# SCR_TC3xx register map
Vendor: Infineon; File version: 1.0
Registers are 8-bit, read-write, reset 0x0 unless marked. A register's access mark holds for its fields unless they carry their own. Offsets are from the block's base; [hi:lo] are bit positions; {n}, {i} and the like mark numbered series; 'fields as' and 'values as' point back to an identical list.

## SCR_SCU — SCR System control unit: SFR paging, clocks, resets, power management, NMI, external interrupts, TriCore data exchange, input selection
Base 0x00040000
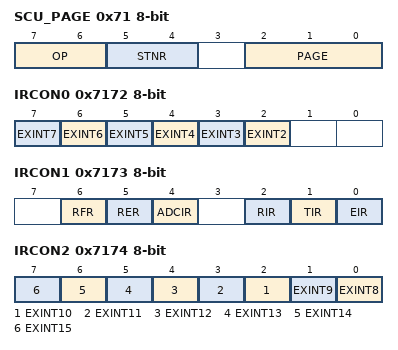
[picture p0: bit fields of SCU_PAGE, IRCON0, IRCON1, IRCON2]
0x71 SCU_PAGE — Page Register for SFRs (SFR 0xF1, RMAP 0)
  [7:6] OP — Operation. [w]
    0=PAGE_MANUAL0 (Manual page mode. The value of STNR is ignored and PAGE is directly written.); 1=PAGE_MANUAL1 (Manual page mode. The value of STNR is ignored and PAGE is directly written); 2=PAGE_SAVE (New page programming with automatic page saving. The value written to the bit positions of PAGE is stored. In parallel, the former contents of PAGE are saved in the storage bit field STx indicated by STNR.); 3=PAGE_RESTORE (Automatic restore page action. The value written to the bit positions PAGE is ignored and instead, PAGE is overwritten by the contents of the storage bit field STx indicated by STNR.)
  [5:4] STNR — Storage Number. This number indicates which storage bitfield is the target of the operation defined by bit OP. If OP = 10B, the contents of PAGE are saved in STx before being overwritten with the new value. If OP = 11B, the contents of PAGE are overwritten by the contents of STx. The value written to bitfield PAGE is ignored. [w]
    {v}=MOD_ST{v} (ST{v} is selected) (v=0..3)
  [2:0] PAGE — Page Bits. When written, the value indicates the new page address. When read, the value indicates the currently active page = addr[y:x+1]. [rw]
    {v}=Selection is PAGE{v} (v=0..7)
0x7172 IRCON0 — Interrupt Request Register 0 (SFR 0xF2, SCU_PAGE page 0, RMAP 0)
  [all] fields
    0=INTERRUPT_REQUEST_HAS_NOT (Interrupt request has not occurred); 1=INTERRUPT_REQUEST_HAS_OCCURRED
  [n] EXINT{n} (n=2..7) — Interrupt Flag for External Interrupt x. This bit is set by hardware and can only be cleared by software. [rwh]
0x7173 IRCON1 — Interrupt Request Register 1 (SFR 0xF3, SCU_PAGE page 0, RMAP 0)
  [all] fields
    values as the fields of IRCON0
  [6] RFR — Receive FIFO Full Interrupt Flag for SSC. This bit is set by hardware, and can only be cleared by software. [rwh]
  [5] RER — Receive FIFO Empty Interrupt Flag for SSC. This bit is set by hardware, and can only be cleared by software. [rwh]
  [4] ADCIR — Interrupt Flag for ADCOMP unit. This bit is set by hardware, and can only be cleared by software. [rwh]
  [2] RIR — Receive Interrupt Flag for SSC. This bit is set by hardware, and can only be cleared by software. [rwh]
  [1] TIR — Transmit Interrupt Flag for SSC. This bit is set by hardware, and can only be cleared by software. [rwh]
  [0] EIR — Error Interrupt Flag for SSC. This bit is set by hardware, and can only be cleared by software. [rwh]
0x7174 IRCON2 — Interrupt Request Register 2 (SFR 0xF4, SCU_PAGE page 0, RMAP 0)
  [all] fields
    values as the fields of IRCON0
  [n-8] EXINT{n} (n=8..15) — Interrupt Flag for External Interrupt x. This bit is set by hardware and can only be cleared by software. [rwh]
0x7175 SCRINTEXCHG — SCR Interrupt Data Exchange Register (SFR 0xF5, SCU_PAGE page 0, RMAP 0)
  [7:0] SCRINT — Data Exchange from SCR to Main Controller. Fast data exchange between SCR and main controller. The data can be read via PMSWCR2.SCRINT in the main SCU. [rwh]
0x7176 TCINTEXCHG ro — TriCore Interrupt Data Exchange Register (SFR 0xF6, SCU_PAGE page 0, RMAP 0)
  [7:0] TCINT — Data Exchange from Main Controller to SCR. Fast data exchange between main controller and SCR. The data can only be read in SCR. [rh]
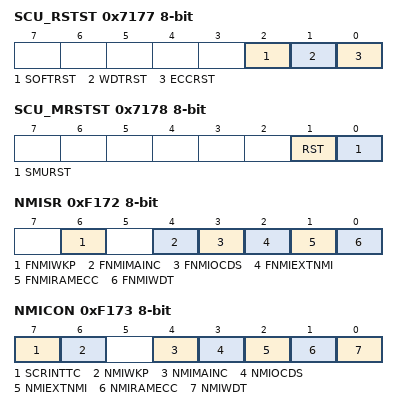
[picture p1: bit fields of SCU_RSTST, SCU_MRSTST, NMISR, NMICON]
0x7177 SCU_RSTST — SCR Reset Status Register (SFR 0xF7, SCU_PAGE page 0, RMAP 0)
  [2] SOFTRST — Soft Reset Indication Bit. This bit can only be set by hardware and cleared by software. [rwh]
    0=NO_SOFT_RESET_HAS_OCCURRED; 1=SOFT_RESET_HAS_OCCURRED
  [1] WDTRST — Watchdog Timer Reset Indication Bit. This bit can only be set by hardware and cleared by software. [rwh]
    0=NO_WATCHDOG_RESET_HAS_OCCURRED; 1=WATCHDOG_RESET_HAS_OCCURRED
  [0] ECCRST — Double Bit ECC Reset Indication Bit. This bit can only be set by hardware and cleared by software. [rwh]
    0=NO_ECC_RESET_HAS_OCCURRED; 1=ECC_RESET_HAS_OCCURRED
0x7178 SCU_MRSTST — Main Reset Status Register (SFR 0xF8, SCU_PAGE page 0, RMAP 0)
  [1] RST — Application Reset Status Bit. This bit can only be set by hardware, and cleared by software. [rwh]
    0=APPLICATION_RESET_IS_NOT (Application reset is not triggered since the last clearing of the bit); 1=APPLICATION_RESET_TRIGGERED
  [0] SMURST — SMU Reset Status Bit. This bit can only be set by hardware, and cleared by software. [rwh]
    0=NO_RESET_ISSUED_BY_SMU_SINCE_THE (No reset issued by SMU since the last clearing of the bit); 1=RESET_ISSUED_BY_SMU
0x7179 SCU_SR ro — SCU Status Register (SFR 0xF9, SCU_PAGE page 0, RMAP 0)
  [3] STBY — Standby Mode Status. [rh]
    0=STANDBY_MODE_NOT_ENTERED; 1=STANDBY_MODE_ENTERED
0xF172 NMISR — NMI Status Register (SFR 0xF2, SCU_PAGE page 1, RMAP 0)
  [6] FNMIWKP — Wake-Up NMI Flag. [rwh]
    0=NO_WAKE_UP_NMI_HAS_OCCURRED; 1=WAKE_UP_NMI_HAS_OCCURRED
  [4] FNMIMAINC — Main Controller NMI Flag. [rwh]
    0=NO_MAIN_CONTROLLER_NMI_HAS (No Main controller NMI has occurred); 1=MAIN_CONTROLLER_NMI_HAS_OCCURRED
  [3] FNMIOCDS — OCDS NMI Flag. [rwh]
    0=NO_OCDS_NMI_HAS_OCCURRED; 1=JTAG_RECEIVING_OR_USER_INTERRUPT (JTAG-receiving or user interrupt request in Monitor Mode has occurred)
  [2] FNMIEXTNMI — External NMI (via EXTNMI pin) Flag. Note:It is recommended to clear the NMISR.FNMIEXTNMI flag before enabling external NMI. [rwh]
    0=NO_EXTERNAL_NMI_VIA_EXTNMI_PIN (No external NMI (via EXTNMI pin) has occurred); 1=EXTERNAL_NMI_VIA_EXTNMI_PIN_HAS (External NMI (via EXTNMI pin) has occurred)
  [1] FNMIRAMECC — RAM Double bit ECC Error NMI Flag. [rwh]
    0=NO_RAM_ECC_NMI_HAS_OCCURRED; 1=RAM_ECC_NMI_HAS_OCCURRED
  [0] FNMIWDT — Watchdog Timer NMI Flag. [rwh]
    0=NO_WATCHDOG_NMI_HAS_OCCURRED; 1=WDT_PRE_WARNING_HAS_OCCURRED
0xF173 NMICON — NMI Control Register (SFR 0xF3, SCU_PAGE page 1, RMAP 0)
  [7] SCRINTTC — CPUx interrupt Enable. Trigger an interrupt to CPUx. This bit will be reset automatically to 0. [rwh]
    0=NO_INTERRUPT_EVENT_IS_TRIGGERED; 1=A_CPUX_INTERRUPT_IS_TRIGGERED
  [6] NMIWKP — Wake-Up NMI Enable. [rw]
    0=WAKE_UP_NMI_IS_DISABLED; 1=WAKE_UP_NMI_IS_ENABLED
  [4] NMIMAINC — Main Controller NMI Enable. [rw]
    0=MAIN_CONTROLLER_NMI_IS_DISABLED; 1=MAIN_CONTROLLER_NMI_IS_ENABLED
  [3] NMIOCDS — OCDS NMI Enable. [rw]
    0=OCDS_NMI_IS_DISABLED; 1=OCDS_NMI_IS_ENABLED
  [2] NMIEXTNMI — External NMI (via EXTNMI pin) NMI Enable. Note:It is recommended to clear the NMISR.FNMIEXTNMI flag before enabling external NMI. [rw]
    0=EXTERNAL_NMI_VIA_EXTNMI_PIN_IS (External NMI (via EXTNMI pin) is disabled); 1=EXTERNAL_NMI_VIA_EXTNMI_PIN_IS_2 (External NMI (via EXTNMI pin) is enabled)
  [1] NMIRAMECC — RAM Double bit ECC Error NMI Enable. [rw]
    0=RAM_DOUBLE_BIT_ECC_ERROR_NMI_IS (RAM double bit ECC error NMI is disabled); 1=RAM_DOUBLE_BIT_ECC_ERROR_NMI_IS_2 (RAM double bit ECC error NMI is enabled)
  [0] NMIWDT — Watchdog Timer NMI Enable. [rw]
    0=WDT_NMI_IS_DISABLED; 1=WDT_NMI_IS_ENABLED
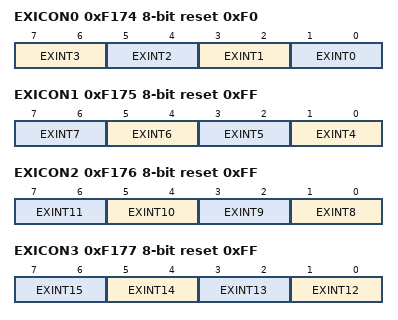
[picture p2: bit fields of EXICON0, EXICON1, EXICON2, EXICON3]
0xF174 EXICON0 reset 0xF0 — External Interrupt Control Register 0 (SFR 0xF4, SCU_PAGE page 1, RMAP 0)
  [7:6] EXINT3 — External Interrupt 3 Trigger Select. [rw]
    0=INT_FALL_EDGE (Interrupt on falling edge); 1=INT_RISE_EDGE (Interrupt on rising edge); 2=INT_BOTH_EDGE (Interrupt on both, rising and falling edge); 3=DISABLE (External interrupt 3 is disabled)
  [5:4] EXINT2 — External Interrupt 2 Trigger Select. [rw]
    0=INT_FALL_EDGE (Interrupt on falling edge); 1=INT_RISE_EDGE (Interrupt on rising edge); 2=INT_BOTH_EDGE (Interrupt on both, rising and falling edge); 3=DISABLE (External interrupt 2 is disabled)
  [3:2] EXINT1 — External Interrupt 1 Trigger Select. [rw]
    0=INT_FALL_EDGE (Interrupt on falling edge); 1=INT_RISE_EDGE (Interrupt on rising edge); 2=INT_BOTH_EDGE (Interrupt on both, rising and falling edge); 3=BYPASS (Bypass the edge detection in SCU. The input signal directly feeds to the core.)
  [1:0] EXINT0 — External Interrupt 0 Trigger Select. [rw]
    values as EXINT1
0xF175 EXICON1 reset 0xFF — External Interrupt Control Register 1 (SFR 0xF5, SCU_PAGE page 1, RMAP 0)
  [2n-7:2n-8] EXINT{n} (n=4..7) — External Interrupt {n} Trigger Select. [rw]
    0=INT_FALL_EDGE (Interrupt on falling edge); 1=INT_RISE_EDGE (Interrupt on rising edge); 2=INT_BOTH_EDGE (Interrupt on both, rising and falling edge); 3=DISABLE (External interrupt {n} is disabled)
0xF176 EXICON2 reset 0xFF — External Interrupt Control Register 2 (SFR 0xF6, SCU_PAGE page 1, RMAP 0)
  [2n-15:2n-16] EXINT{n} (n=8..11) — External Interrupt {n} Trigger Select. [rw]
    values as EXICON1.EXINT4
0xF177 EXICON3 reset 0xFF — External Interrupt Control Register 3 (SFR 0xF7, SCU_PAGE page 1, RMAP 0)
  [2n-23:2n-24] EXINT{n} (n=12..15) — External Interrupt {n} Trigger Select. [rw]
    values as EXICON1.EXINT4
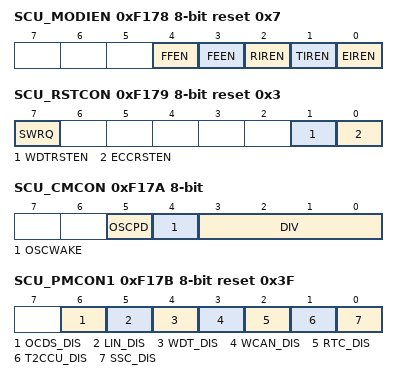
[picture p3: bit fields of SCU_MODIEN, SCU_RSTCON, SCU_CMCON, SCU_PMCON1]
0xF178 SCU_MODIEN reset 0x7 — Peripheral Interrupt Enable Register (SFR 0xF8, SCU_PAGE page 1, RMAP 0)
  [4] FFEN — SSC Receive FIFO Full Interrupt Enable. [rw]
    0=RECEIVE_FIFO_FULL_INTERRUPT_IS (Receive FIFO full interrupt is disabled); 1=RECEIVE_FIFO_FULL_INTERRUPT_IS_2 (Receive FIFO full interrupt is enabled)
  [3] FEEN — SSC Receive FIFO Empty Interrupt Enable. [rw]
    0=RECEIVE_FIFO_EMPTY_INTERRUPT_IS (Receive FIFO empty interrupt is disabled); 1=RECEIVE_FIFO_EMPTY_INTERRUPT_IS_2 (Receive FIFO empty interrupt is enabled)
  [2] RIREN — SSC Receive Interrupt Enable. [rw]
    0=RECEIVE_INTERRUPT_IS_DISABLED; 1=RECEIVE_INTERRUPT_IS_ENABLED
  [1] TIREN — SSC Transmit Interrupt Enable. [rw]
    0=TRANSMIT_INTERRUPT_IS_DISABLED; 1=TRANSMIT_INTERRUPT_IS_ENABLED
  [0] EIREN — SSC Error Interrupt Enable. [rw]
    0=ERROR_INTERRUPT_IS_DISABLED; 1=ERROR_INTERRUPT_IS_ENABLED
0xF179 SCU_RSTCON reset 0x3 — Reset Control Register (SFR 0xF9, SCU_PAGE page 1, RMAP 0)
  [7] SWRQ — Soft Reset Request. This bit is automatically cleared by hardware. The SWRQ bit is a protected bit. When the Protection Scheme is activated, this bit cannot be written directly. For more information on Protection Scheme, see Section "Miscellaneous Control". [rwh]
    0=NO_ACTION; 1=ON_SET_SOFT_RESET_IS_REQUESTED
  [1] WDTRSTEN — Watchdog Reset Enable Bit. [rw]
    0=WATCHDOG_RESET_IS_DISABLED; 1=WATCHDOG_RESET_IS_ENABLED
  [0] ECCRSTEN — Double Bit ECC Reset Enable Bit. [rw]
    0=ECC_RESET_IS_DISABLED; 1=ECC_RESET_IS_ENABLED
0xF17A SCU_CMCON — Clock Control Register (SFR 0xFA, SCU_PAGE page 1, RMAP 0)
  [5] OSCPD — 100 MHz Oscillator Power Down Control in Standby Mode. This bit is used to power down the 100 MHz oscillator in standby mode. The OSCPD bit is a protected bit. When the Protection Scheme is activated, this bit cannot be written directly. For more information on Protection Scheme, see Section "Miscellaneous Control". [rwh]
    0=V100_MHZ_OSCILLATOR_IS_NOT_POWERED (100 MHz oscillator is not powered down in standby mode); 1=V100_MHZ_OSCILLATOR_IS_POWERED (100 MHz oscillator is powered down in standby mode)
  [4] OSCWAKE — Oscillator Wake-Up. Automatic oscillator wake-up. [rw]
    0=MODULES_CANNOT_CLEAR_OSCPD; 1=MODULES_CAN_CLEAR_OSCPD_AND (Modules can clear OSCPD and enable 100 MHz oscillator)
  [3:0] DIV — Clock Divider. [rw]
    0=DIV = 5; fSYS = 20 MHz; 1=DIV = 8; fSYS = 12.5 MHz; 2=DIV = 10; fSYS = 10 MHz; 3=DIV = 16; fSYS = 6.25 MHz; 4=DIV = 20; fSYS = 5 MHz; 5=DIV = 32; fSYS = 3.125 MHz; 6=DIV = 40; fSYS = 2.5 MHz; 7=DIV = 50; fSYS = 2 MHz; 8=DIV = 80; fSYS = 1.25 MHz; 9=DIV = 100; fSYS = 1 MHz; 10=DIV = 125; fSYS = 0.8 MHz; 11=DIV = 160; fSYS = 0.625 MHz; 12=DIV = 200; fSYS = 0.5 MHz; 13=DIV = 250; fSYS = 0.4 MHz
0xF17B SCU_PMCON1 reset 0x3F — Peripheral Management Control Register 1 (SFR 0xFB, SCU_PAGE page 1, RMAP 0)
  [6] OCDS_DIS — OCDS Disable Request (active high). [rw]
    0=OCDS_AND_DEBUG_SYSTEM_IS_IN (OCDS and Debug System is in normal operation (this is the default value, and the clock to OCDS and Debug System is enabled by default)); 1=REQUEST_TO_DISABLE_THE_OCDS_AND (Request to disable the OCDS and Debug System (during normal operation, application may choose to gate the OCDS and Debug System clock to save power))
  [5] LIN_DIS — LIN Disable Request (active high). [rw]
    0=LIN_BAUDRATE_GENERATOR_AND (LIN baudrate generator and detector are in normal operation); 1=REQUEST_TO_DISABLE_THE_LIN (Request to disable the LIN baudrate generator and detector (default))
  [4] WDT_DIS — Watchdog Disable Request (active high). [rw]
    0=WATCHDOG_IS_IN_NORMAL_OPERATION; 1=REQUEST_TO_DISABLE_THE_WATCHDOG (Request to disable the Watchdog (default))
  [3] WCAN_DIS — WCAN Disable Request (active high). [rw]
    0=WCAN_IS_IN_NORMAL_OPERATION; 1=REQUEST_TO_DISABLE_THE_WCAN (Request to disable the WCAN (default))
  [2] RTC_DIS — RTC Disable Request (active high). [rw]
    0=RTC_IS_IN_NORMAL_OPERATION; 1=REQUEST_TO_DISABLE_THE_RTC (Request to disable the RTC (default))
  [1] T2CCU_DIS — T2CCU Disable Request (active high). [rw]
    0=T2CCU_IS_IN_NORMAL_OPERATION; 1=REQUEST_TO_DISABLE_THE_T2CCU (Request to disable the T2CCU (default))
  [0] SSC_DIS — SSC Disable Request (active high). [rw]
    0=SSC_IS_IN_NORMAL_OPERATION; 1=REQUEST_TO_DISABLE_THE_SSC (Request to disable the SSC (default))
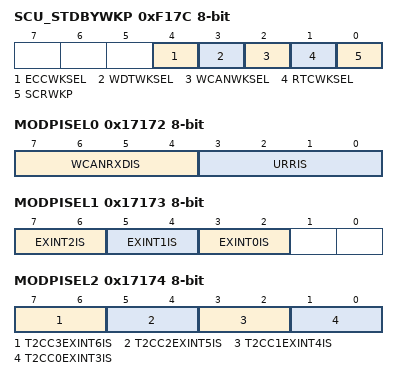
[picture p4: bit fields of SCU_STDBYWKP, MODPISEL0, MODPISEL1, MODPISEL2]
0xF17C SCU_STDBYWKP — Standby Mode Wake-Up Register (SFR 0xFC, SCU_PAGE page 1, RMAP 0)
  [4] ECCWKSEL — RAM ECC Wake-Up Select from Standby Mode. [rw]
    0=WAKE_UP_FROM_STANDBY_MODE_IS_NOT (Wake-up from standby mode is not selected when RAM ECC event occurred); 1=WAKE_UP_FROM_STANDBY_MODE_IS (Wake-up from standby mode is selected when RAM ECC event occurred)
  [3] WDTWKSEL — WDT Wake-Up Select from Standby Mode. [rw]
    0=WAKE_UP_FROM_STANDBY_MODE_IS_NOT (Wake-up from standby mode is not selected when WDT event occurred); 1=WAKE_UP_FROM_STANDBY_MODE_IS (Wake-up from standby mode is selected when WDT event occurred)
  [2] WCANWKSEL — WCAN Interrupt Wake-Up Select from Standby Mode. [rw]
    0=WAKE_UP_FROM_STANDBY_MODE_VIA (Wake-up from standby mode via WCAN Interrupt is not selected); 1=WAKE_UP_FROM_STANDBY_MODE_VIA_2 (Wake-up from standby mode via WCAN Interrupt is selected)
  [1] RTCWKSEL — RTC Wake-Up Select from Standby Mode. [rw]
    0=WAKE_UP_FROM_STANDBY_MODE_VIA_RTC (Wake-up from standby mode via RTC is not selected); 1=WAKE_UP_FROM_STANDBY_MODE_VIA_RTC_2 (Wake-up from standby mode via RTC is selected)
  [0] SCRWKP — Software Wake-Up from Standby Mode. This bit is automatically cleared by hardware. [rwh]
    0=NO_REQUEST_TO_TRIGGER_A_WAKE_UP (No request to trigger a wake-up from standby mode); 1=TRIGGER_A_WAKE_UP_FROM_STANDBY (Trigger a wake-up from standby mode)
0x17172 MODPISEL0 — Peripheral Input Select Register 0 (SFR 0xF2, SCU_PAGE page 2, RMAP 0)
  [7:4] WCANRXDIS — WCAN Receiver Input Select. others, Reserved [rw]
    0=WCANRXDA (WCAN Receiver Input WCANRXDA is selected); 1=WCANRXDB (WCAN Receiver Input WCANRXDB is selected); 2=WCANRXDC (WCAN Receiver Input WCANRXDC is selected); 3=WCANRXDD (WCAN Receiver Input WCANRXDD is selected); 4=WCANRXDE (WCAN Receiver Input WCANRXDE is selected); 5=WCANRXDF (WCAN Receiver Input WCANRXDF is selected); 6=WCANRXDG (WCAN Receiver Input WCANRXDG is selected)
  [3:0] URRIS — UART Receiver Input Select. others, Reserved [rw]
    0=UART_RXDA (UART Receiver Input RXDA is selected); 1=UART_RXDB (UART Receiver Input RXDB is selected); 2=UART_RXDC (UART Receiver Input RXDC is selected); 3=UART_RXDD (UART Receiver Input RXDD is selected); 4=UART_RXDE (UART Receiver Input RXDE is selected); 5=UART_RXDF (UART Receiver Input RXDF is selected); 6=UART_RXDG (UART Receiver Input RXDG is selected)
0x17173 MODPISEL1 — Peripheral Input Select Register 1 (SFR 0xF3, SCU_PAGE page 2, RMAP 0)
  [7:6] EXINT2IS — External Interrupt Input 2 Input Select. [rw]
    0=EXINT2A (External Interrupt Input EXINT2A is selected); 1=EXINT2B (External Interrupt Input EXINT2B is selected); 2=EXINT2C (External Interrupt Input EXINT2C is selected); 3=EXINT2D (External Interrupt Input EXINT2D is selected)
  [5:4] EXINT1IS — External Interrupt Input 1 Input Select. [rw]
    0=EXINT1A (External Interrupt Input EXINT1A is selected); 1=EXINT1B (External Interrupt Input EXINT1B is selected); 2=EXINT1C (External Interrupt Input EXINT1C is selected); 3=EXINT1D (External Interrupt Input EXINT1D is selected)
  [3:2] EXINT0IS — External Interrupt Input 0 Input Select. [rw]
    0=EXINT0A (External Interrupt Input EXINT0A is selected); 1=EXINT0B (External Interrupt Input EXINT0B is selected); 2=EXINT0C (External Interrupt Input EXINT0C is selected); 3=EXINT0D (External Interrupt Input EXINT0D is selected)
0x17174 MODPISEL2 — Peripheral Input Select Register 2 (SFR 0xF4, SCU_PAGE page 2, RMAP 0)
  [7:6] T2CC3EXINT6IS — External Interrupt 6/T2CCU Capture Channel 3 Input Select. [rw]
    0=T2CC3A (External Interrupt 6 Input EXINT6A/T2CCU Capture Channel 3 Input T2CC3A is selected); 1=T2CC3B (External Interrupt 6 Input EXINT6B/T2CCU Capture Channel 3 Input T2CC3B is selected); 2=T2CC3C (External Interrupt 6 Input EXINT6C/T2CCU Capture Channel 3 Input T2CC3C is selected); 3=T2CC3D (Reserved)
  [5:4] T2CC2EXINT5IS — External Interrupt 5/T2CCU Capture Channel 2 Input Select. [rw]
    0=T2CC2A (External Interrupt 5 Input EXINT5A/T2CCU Capture Channel 2 Input T2CC2A is selected); 1=T2CC2B (External Interrupt 5 Input EXINT5B/T2CCU Capture Channel 2 Input T2CC2B is selected); 2=T2CC2C (External Interrupt 5 Input EXINT5C/T2CCU Capture Channel 2 Input T2CC2C is selected); 3=T2CC2D (Reserved)
  [3:2] T2CC1EXINT4IS — External Interrupt 4/T2CCU Capture Channel 1 Input Select. [rw]
    0=T2CC1A (External Interrupt 4 Input EXINT4A/T2CCU Capture Channel 1 Input T2CC1A is selected); 1=T2CC1B (External Interrupt 4 Input EXINT4B/T2CCU Capture Channel 1 Input T2CC1B is selected); 2=T2CC1C (External Interrupt 4 Input EXINT4C/T2CCU Capture Channel 1 Input T2CC1C is selected); 3=T2CC1D (Reserved)
  [1:0] T2CC0EXINT3IS — External Interrupt 3/T2CCU Capture Channel 0 Input Select. [rw]
    0=T2CC0A (External Interrupt 3 Input EXINT0A/T2CCU Capture Channel 0 Input T2CC0A is selected); 1=T2CC0B (External Interrupt 3 Input EXINT0B/T2CCU Capture Channel 0 Input T2CC0B is selected); 2=T2CC0C (External Interrupt 3 Input EXINT0C/T2CCU Capture Channel 0 Input T2CC0C is selected); 3=T2CC0D (Reserved)
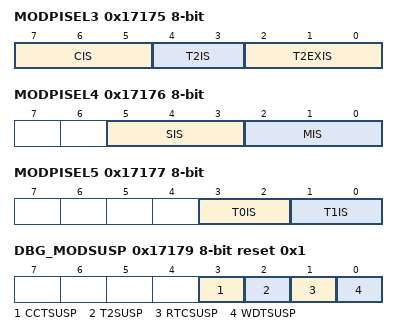
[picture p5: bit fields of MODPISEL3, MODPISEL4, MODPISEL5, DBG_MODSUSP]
0x17175 MODPISEL3 — Peripheral Input Select Register 3 (SFR 0xF5, SCU_PAGE page 2, RMAP 0)
  [7:5] CIS — Slave Mode Clock Input Select. others, Reserved [rw]
    0=SCLKA (SSC Slave Clock Input SCLKA is selected); 1=SCLKB (SSC Slave Clock Input SCLKB is selected); 2=SCLKC (SSC Slave Clock Input SCLKC is selected)
  [4:3] T2IS — Timer 2 Input Select. [rw]
    0=T2A (Timer 2 Input T2A is selected); 1=T2B (Timer 2 Input T2B is selected); 2=T2C (Timer 2 Input T2C is selected)
  [2:0] T2EXIS — Timer 2 External Input Select. [rw]
    0=T2EXA (Timer 2 Input T2EXA is selected); 1=T2EXB (Timer 2 Input T2EXB is selected); 2=T2EXC (Timer 2 Input T2EXC is selected); 3=T2EXD (Timer 2 Input T2EXD is selected); 4=T2EXE (Timer 2 Input T2EXE is selected); 5=T2EXF (Timer 2 Input T2EXF is selected); 6=T2EXG (Timer 2 Input T2EXG is selected); 7=T2EXH (Timer 2 Input T2EXH is selected)
0x17176 MODPISEL4 — Peripheral Input Select Register 4 (SFR 0xF6, SCU_PAGE page 2, RMAP 0)
  [5:3] SIS — Slave Mode Receive Input Select. others, Reserved [rw]
    0=MTSRA (SSC Slave Receiver Input MTSRA is selected); 1=MTSRB (SSC Slave Receiver Input MTSRB is selected); 2=MTSRC (SSC Slave Receiver Input MTSRC is selected)
  [2:0] MIS — Master Mode Receive Input Select. others, Reserved [rw]
    0=MRSTA (SSC Master Receiver Input MRSTA is selected); 1=MRSTB (SSC Master Receiver Input MRSTB is selected); 2=MRSTC (SSC Master Receiver Input MRSTC is selected)
0x17177 MODPISEL5 — Peripheral Input Select Register 5 (SFR 0xF7, SCU_PAGE page 2, RMAP 0)
  [3:2] T0IS — Timer 0 Input Select. [rw]
    0=T1A (Timer 0 Input T0A is selected); 1=T1B (Timer 0 Input T0B is selected); 2=T1C (Timer 0 Input T0C is selected)
  [1:0] T1IS — Timer 1 Input Select. [rw]
    0=T1A (Timer 1 Input T1A is selected); 1=T1B (Timer 1 Input T1B is selected); 2=T1C (Timer 1 Input T1C is selected)
0x17179 DBG_MODSUSP reset 0x1 — Module Suspend Control Register (SFR 0xF9, SCU_PAGE page 2, RMAP 0)
  [3] CCTSUSP — Compare/Capture Timer (CCT) Debug Suspend Bit. [rw]
    0=CCT_WILL_NOT_BE_SUSPENDED; 1=CCT_WILL_BE_SUSPENDED
  [2] T2SUSP — Timer 2 Debug Suspend Bit. [rw]
    0=TIMER_2_WILL_NOT_BE_SUSPENDED; 1=TIMER_2_WILL_BE_SUSPENDED
  [1] RTCSUSP — Real-Time Clock Debug Suspend Bit. [rw]
    0=REAL_TIME_CLOCK_WILL_NOT_BE (Real-Time clock will not be suspended); 1=REAL_TIME_CLOCK_WILL_BE_SUSPENDED
  [0] WDTSUSP — SCU Watchdog Timer Debug Suspend Bit. [rw]
    0=WDT_WILL_NOT_BE_SUSPENDED; 1=WDT_WILL_BE_SUSPENDED
